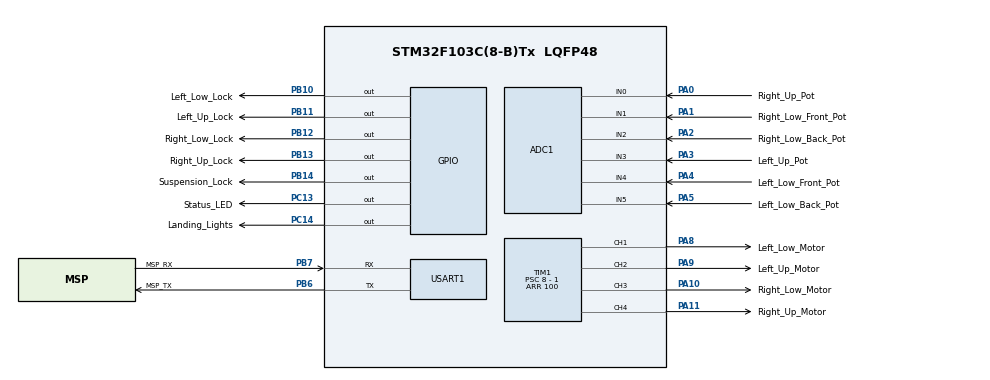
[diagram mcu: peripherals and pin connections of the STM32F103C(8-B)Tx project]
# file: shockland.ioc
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ADC1.Channel-0\#ChannelRegularConversion=ADC_CHANNEL_0
ADC1.Channel-1\#ChannelRegularConversion=ADC_CHANNEL_0
ADC1.Channel-2\#ChannelRegularConversion=ADC_CHANNEL_0
ADC1.Channel-3\#ChannelRegularConversion=ADC_CHANNEL_0
ADC1.Channel-4\#ChannelRegularConversion=ADC_CHANNEL_0
ADC1.Channel-5\#ChannelRegularConversion=ADC_CHANNEL_0
ADC1.NbrOfConversion=6
ADC1.NbrOfConversionFlag=1
ADC1.Rank-0\#ChannelRegularConversion=1
ADC1.Rank-1\#ChannelRegularConversion=2
ADC1.Rank-2\#ChannelRegularConversion=3
ADC1.Rank-3\#ChannelRegularConversion=4
ADC1.Rank-4\#ChannelRegularConversion=5
ADC1.Rank-5\#ChannelRegularConversion=6
ADC1.SamplingTime-0\#ChannelRegularConversion=ADC_SAMPLETIME_1CYCLE_5
ADC1.SamplingTime-1\#ChannelRegularConversion=ADC_SAMPLETIME_1CYCLE_5
ADC1.SamplingTime-2\#ChannelRegularConversion=ADC_SAMPLETIME_1CYCLE_5
ADC1.SamplingTime-3\#ChannelRegularConversion=ADC_SAMPLETIME_1CYCLE_5
ADC1.SamplingTime-4\#ChannelRegularConversion=ADC_SAMPLETIME_1CYCLE_5
ADC1.SamplingTime-5\#ChannelRegularConversion=ADC_SAMPLETIME_1CYCLE_5
ADC1.master=1
Dma.ADC1.0.Direction=DMA_PERIPH_TO_MEMORY
Dma.ADC1.0.Instance=DMA1_Channel1
Dma.ADC1.0.MemDataAlignment=DMA_MDATAALIGN_HALFWORD
Dma.ADC1.0.MemInc=DMA_MINC_ENABLE
Dma.ADC1.0.Mode=DMA_CIRCULAR
Dma.ADC1.0.PeriphDataAlignment=DMA_PDATAALIGN_HALFWORD
Dma.ADC1.0.PeriphInc=DMA_PINC_DISABLE
Dma.ADC1.0.Priority=DMA_PRIORITY_LOW
Dma.Request0=ADC1
Mcu.Family=STM32F1
Mcu.Name=STM32F103C(8-B)Tx
Mcu.Package=LQFP48
Mcu.UserConstants=MotorID_Left_Up,0x0;MotorID_Left_Low,0x4;MotorID_Right_Up,0x8;MotorID_Right_Low,0xC
NVIC.DMA1_Channel1_IRQn=true\:0\:0\:false\:false\:true\:false\:true\:true
NVIC.PriorityGroup=NVIC_PRIORITYGROUP_4
PA0-WKUP.GPIO_Label=Right_Up_Pot
PA0-WKUP.Signal=ADCx_IN0
PA1.GPIO_Label=Right_Low_Front_Pot
PA1.Signal=ADCx_IN1
PA10.GPIO_Label=Right_Low_Motor
PA10.Signal=S_TIM1_CH3
PA11.GPIO_Label=Right_Up_Motor
PA11.Signal=S_TIM1_CH4
PA13.Mode=Serial_Wire
PA13.Signal=SYS_JTMS-SWDIO
PA14.Mode=Serial_Wire
PA14.Signal=SYS_JTCK-SWCLK
PA2.GPIO_Label=Right_Low_Back_Pot
PA2.Signal=ADCx_IN2
PA3.GPIO_Label=Left_Up_Pot
PA3.Signal=ADCx_IN3
PA4.GPIO_Label=Left_Low_Front_Pot
PA4.Signal=ADCx_IN4
PA5.GPIO_Label=Left_Low_Back_Pot
PA5.Signal=ADCx_IN5
PA8.GPIO_Label=Left_Low_Motor
PA8.Signal=S_TIM1_CH1
PA9.GPIO_Label=Left_Up_Motor
PA9.Signal=S_TIM1_CH2
PB10.GPIO_Label=Left_Low_Lock
PB10.Signal=GPIO_Output
PB11.GPIO_Label=Left_Up_Lock
PB11.Signal=GPIO_Output
PB12.GPIO_Label=Right_Low_Lock
PB12.Signal=GPIO_Output
PB13.GPIO_Label=Right_Up_Lock
PB13.Signal=GPIO_Output
PB14.GPIO_Label=Suspension_Lock
PB14.Signal=GPIO_Output
PB6.GPIO_Label=MSP_TX
PB6.Mode=Asynchronous
PB6.Signal=USART1_TX
PB7.GPIO_Label=MSP_RX
PB7.Mode=Asynchronous
PB7.Signal=USART1_RX
PC13-TAMPER-RTC.GPIO_Label=Status_LED
PC13-TAMPER-RTC.Signal=GPIO_Output
PC14-OSC32_IN.GPIO_Label=Landing_Lights
PC14-OSC32_IN.Signal=GPIO_Output
PD0-OSC_IN.Mode=HSE-External-Clock-Source
PD0-OSC_IN.Signal=RCC_OSC_IN
PD1-OSC_OUT.Mode=HSE-External-Clock-Source
PD1-OSC_OUT.Signal=RCC_OSC_OUT
ProjectManager.HeapSize=0x200
ProjectManager.StackSize=0x400
ProjectManager.TargetToolchain=Makefile
RCC.ADCPresc=RCC_ADCPCLK2_DIV4
RCC.APB1Freq_Value=8000000
RCC.APB2Freq_Value=8000000
SH.ADCx_IN0.0=ADC1_IN0,IN0
SH.ADCx_IN1.0=ADC1_IN1,IN1
SH.ADCx_IN2.0=ADC1_IN2,IN2
SH.ADCx_IN3.0=ADC1_IN3,IN3
SH.ADCx_IN4.0=ADC1_IN4,IN4
SH.ADCx_IN5.0=ADC1_IN5,IN5
SH.S_TIM1_CH1.0=TIM1_CH1,PWM Generation1 CH1
SH.S_TIM1_CH2.0=TIM1_CH2,PWM Generation2 CH2
SH.S_TIM1_CH3.0=TIM1_CH3,PWM Generation3 CH3
SH.S_TIM1_CH4.0=TIM1_CH4,PWM Generation4 CH4
TIM1.Channel-PWM\ Generation1\ CH1=TIM_CHANNEL_1
TIM1.Channel-PWM\ Generation2\ CH2=TIM_CHANNEL_2
TIM1.Channel-PWM\ Generation3\ CH3=TIM_CHANNEL_3
TIM1.Channel-PWM\ Generation4\ CH4=TIM_CHANNEL_4
TIM1.Period=100
TIM1.Prescaler=8 - 1
USART1.VirtualMode=VM_ASYNC
VP_TIM1_VS_ClockSourceINT.Mode=Internal
board=custom

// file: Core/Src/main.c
/* USER CODE BEGIN Header */
/**
 ******************************************************************************
 * @file           : main.c
 * @brief          : Main program body
 ******************************************************************************
 * @attention
 *
 * Copyright (c) 2023 STMicroelectronics.
 * All rights reserved.
 *
 * This software is licensed under terms that can be found in the LICENSE file
 * in the root directory of this software component.
 * If no LICENSE file comes with this software, it is provided AS-IS.
 *
 ******************************************************************************
 */
/* USER CODE END Header */
#include "main.h"
#include "adc.h"
#include "dma.h"
#include "gpio.h"
#include "tim.h"
#include "usart.h"

/* USER CODE BEGIN PV */
uint32_t potentiometer_values[6];
/* USER CODE END PV */

void SystemClock_Config(void);

int main(void) {

    /* MCU
     * Configuration--------------------------------------------------------*/

    /* Reset of all peripherals, Initializes the Flash interface and the
     * Systick. */
    HAL_Init();

    /* Configure the system clock */
    SystemClock_Config();

    /* Initialize all configured peripherals */
    MX_GPIO_Init();
    MX_DMA_Init();
    MX_ADC1_Init();
    MX_TIM1_Init();
    MX_USART1_UART_Init();
    /* USER CODE BEGIN 2 */
    HAL_ADC_Start_DMA(&hadc1, potentiometer_values, 6);
    HAL_TIM_PWM_Start(&htim1, TIM_CHANNEL_ALL);
    /* USER CODE END 2 */

    /* Infinite loop */
    while (1) {

    }
}

void SystemClock_Config(void) {
    RCC_OscInitTypeDef RCC_OscInitStruct = {0};
    RCC_ClkInitTypeDef RCC_ClkInitStruct = {0};
    RCC_PeriphCLKInitTypeDef PeriphClkInit = {0};

    /** Initializes the RCC Oscillators according to the specified parameters
     * in the RCC_OscInitTypeDef structure.
     */
    RCC_OscInitStruct.OscillatorType = RCC_OSCILLATORTYPE_HSI;
    RCC_OscInitStruct.HSIState = RCC_HSI_ON;
    RCC_OscInitStruct.HSICalibrationValue = RCC_HSICALIBRATION_DEFAULT;
    RCC_OscInitStruct.PLL.PLLState = RCC_PLL_NONE;
    if (HAL_RCC_OscConfig(&RCC_OscInitStruct) != HAL_OK) {
        Error_Handler();
    }

    /** Initializes the CPU, AHB and APB buses clocks
     */
    RCC_ClkInitStruct.ClockType = RCC_CLOCKTYPE_HCLK | RCC_CLOCKTYPE_SYSCLK |
                                  RCC_CLOCKTYPE_PCLK1 | RCC_CLOCKTYPE_PCLK2;
    RCC_ClkInitStruct.SYSCLKSource = RCC_SYSCLKSOURCE_HSI;
    RCC_ClkInitStruct.AHBCLKDivider = RCC_SYSCLK_DIV1;
    RCC_ClkInitStruct.APB1CLKDivider = RCC_HCLK_DIV1;
    RCC_ClkInitStruct.APB2CLKDivider = RCC_HCLK_DIV1;

    if (HAL_RCC_ClockConfig(&RCC_ClkInitStruct, FLASH_LATENCY_0) != HAL_OK) {
        Error_Handler();
    }
    PeriphClkInit.PeriphClockSelection = RCC_PERIPHCLK_ADC;
    PeriphClkInit.AdcClockSelection = RCC_ADCPCLK2_DIV4;
    if (HAL_RCCEx_PeriphCLKConfig(&PeriphClkInit) != HAL_OK) {
        Error_Handler();
    }
}

/* USER CODE BEGIN 4 */

void SetMotorPWM(uint8_t motor, uint8_t percentage) {
    __HAL_TIM_SetCompare(&htim1, motor, percentage);
}

/* USER CODE END 4 */

void Error_Handler(void) {
    /* USER CODE BEGIN Error_Handler_Debug */
    /* User can add his own implementation to report the HAL error return state
     */
    __disable_irq();
    while (1) {
    }
    /* USER CODE END Error_Handler_Debug */
}

#ifdef USE_FULL_ASSERT
/**
 * @brief  Reports the name of the source file and the source line number
 *         where the assert_param error has occurred.
 * @param  file: pointer to the source file name
 * @param  line: assert_param error line source number
 * @retval None
 */
void assert_failed(uint8_t *file, uint32_t line) {
    /* USER CODE BEGIN 6 */
    /* User can add his own implementation to report the file name and line
       number, ex: printf("Wrong parameters value: file %s on line %d\r\n",
       file, line) */
    /* USER CODE END 6 */
}
#endif /* USE_FULL_ASSERT */
